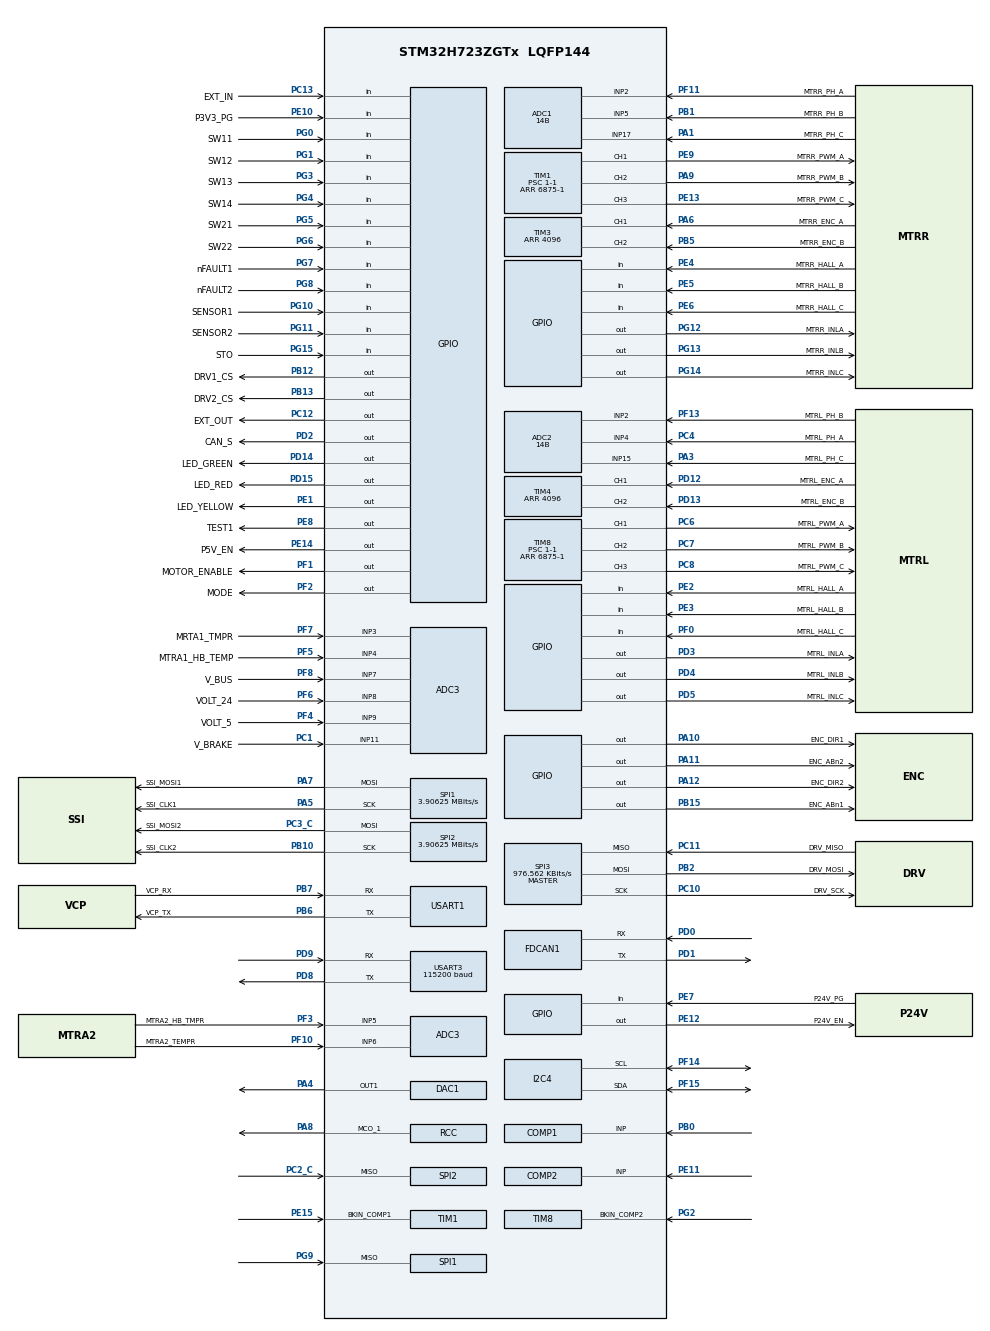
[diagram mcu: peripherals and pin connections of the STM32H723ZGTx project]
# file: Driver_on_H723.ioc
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ADC1.ClockPrescaler=ADC_CLOCK_ASYNC_DIV4
ADC1.ClockPrescalerADC3=ADC_CLOCK_ASYNC_DIV1
ADC1.ConversionDataManagement=ADC_CONVERSIONDATA_DR
ADC1.EnableInjectedConversion=ENABLE
ADC1.EnableRegularConversion=DISABLE
ADC1.ExternalTrigInjecConv=ADC_EXTERNALTRIGINJEC_T1_TRGO
ADC1.ExternalTrigInjecConvEdge=ADC_EXTERNALTRIGINJECCONV_EDGE_RISINGFALLING
ADC1.InjNumberOfConversion=2
ADC1.InjectedChannel-1\#ChannelInjectedConversion=ADC_CHANNEL_2
ADC1.InjectedChannel-2\#ChannelInjectedConversion=ADC_CHANNEL_5
ADC1.InjectedOffsetNumber-1\#ChannelInjectedConversion=ADC_OFFSET_NONE
ADC1.InjectedOffsetNumber-2\#ChannelInjectedConversion=ADC_OFFSET_NONE
ADC1.InjectedOffsetSaturation-1\#ChannelInjectedConversion=DISABLE
ADC1.InjectedOffsetSaturation-2\#ChannelInjectedConversion=DISABLE
ADC1.InjectedRank-1\#ChannelInjectedConversion=1
ADC1.InjectedRank-2\#ChannelInjectedConversion=2
ADC1.InjectedSamplingTime-1\#ChannelInjectedConversion=ADC_SAMPLETIME_1CYCLE_5
ADC1.InjectedSamplingTime-2\#ChannelInjectedConversion=ADC_SAMPLETIME_1CYCLE_5
ADC1.Overrun=ADC_OVR_DATA_PRESERVED
ADC1.Resolution=ADC_RESOLUTION_14B
ADC1.injectedQueueMode=DISABLE
ADC1.master=1
ADC2.ClockPrescaler=ADC_CLOCK_ASYNC_DIV4
ADC2.ClockPrescalerADC3=ADC_CLOCK_ASYNC_DIV1
ADC2.ConversionDataManagement=ADC_CONVERSIONDATA_DR
ADC2.EnableInjectedConversion=ENABLE
ADC2.EnableRegularConversion=DISABLE
ADC2.ExternalTrigInjecConv=ADC_EXTERNALTRIGINJEC_T8_TRGO
ADC2.ExternalTrigInjecConvEdge=ADC_EXTERNALTRIGINJECCONV_EDGE_RISINGFALLING
ADC2.InjNumberOfConversion=2
ADC2.InjectedChannel-7\#ChannelInjectedConversion=ADC_CHANNEL_4
ADC2.InjectedChannel-8\#ChannelInjectedConversion=ADC_CHANNEL_2
ADC2.InjectedOffsetNumber-7\#ChannelInjectedConversion=ADC_OFFSET_NONE
ADC2.InjectedOffsetNumber-8\#ChannelInjectedConversion=ADC_OFFSET_NONE
ADC2.InjectedOffsetSaturation-7\#ChannelInjectedConversion=DISABLE
ADC2.InjectedOffsetSaturation-8\#ChannelInjectedConversion=DISABLE
ADC2.InjectedRank-7\#ChannelInjectedConversion=1
ADC2.InjectedRank-8\#ChannelInjectedConversion=2
ADC2.InjectedSamplingTime-7\#ChannelInjectedConversion=ADC_SAMPLETIME_1CYCLE_5
ADC2.InjectedSamplingTime-8\#ChannelInjectedConversion=ADC_SAMPLETIME_1CYCLE_5
ADC2.Resolution=ADC_RESOLUTION_14B
ADC3.Channel-0\#ChannelRegularConversion=ADC_CHANNEL_3
ADC3.Channel-1\#ChannelRegularConversion=ADC_CHANNEL_4
ADC3.Channel-10\#ChannelRegularConversion=ADC_CHANNEL_VREFINT
ADC3.Channel-2\#ChannelRegularConversion=ADC_CHANNEL_5
ADC3.Channel-3\#ChannelRegularConversion=ADC_CHANNEL_6
ADC3.Channel-4\#ChannelRegularConversion=ADC_CHANNEL_7
ADC3.Channel-5\#ChannelRegularConversion=ADC_CHANNEL_8
ADC3.Channel-6\#ChannelRegularConversion=ADC_CHANNEL_9
ADC3.Channel-7\#ChannelRegularConversion=ADC_CHANNEL_11
ADC3.Channel-8\#ChannelRegularConversion=ADC_CHANNEL_VBAT
ADC3.Channel-9\#ChannelRegularConversion=ADC_CHANNEL_TEMPSENSOR
ADC3.ClockPrescaler=ADC_CLOCK_ASYNC_DIV4
ADC3.ClockPrescalerADC3=ADC_CLOCK_ASYNC_DIV1
ADC3.ContinuousConvMode=ENABLE
ADC3.DMAContinuousRequests=DISABLE
ADC3.NbrOfConversion=11
ADC3.NbrOfConversionFlag=1
ADC3.OffsetNumber-1\#ChannelRegularConversion=ADC_OFFSET_NONE
ADC3.OffsetNumber-10\#ChannelRegularConversion=ADC_OFFSET_NONE
ADC3.OffsetNumber-2\#ChannelRegularConversion=ADC_OFFSET_NONE
ADC3.OffsetNumber-3\#ChannelRegularConversion=ADC_OFFSET_NONE
ADC3.OffsetNumber-4\#ChannelRegularConversion=ADC_OFFSET_NONE
ADC3.OffsetNumber-5\#ChannelRegularConversion=ADC_OFFSET_NONE
ADC3.OffsetNumber-6\#ChannelRegularConversion=ADC_OFFSET_NONE
ADC3.OffsetNumber-7\#ChannelRegularConversion=ADC_OFFSET_NONE
ADC3.OffsetNumber-8\#ChannelRegularConversion=ADC_OFFSET_NONE
ADC3.OffsetNumber-9\#ChannelRegularConversion=ADC_OFFSET_NONE
ADC3.OffsetSign-1\#ChannelRegularConversion=ADC3_OFFSET_SIGN_NEGATIVE
ADC3.OffsetSign-10\#ChannelRegularConversion=ADC3_OFFSET_SIGN_NEGATIVE
ADC3.OffsetSign-2\#ChannelRegularConversion=ADC3_OFFSET_SIGN_NEGATIVE
ADC3.OffsetSign-3\#ChannelRegularConversion=ADC3_OFFSET_SIGN_NEGATIVE
ADC3.OffsetSign-4\#ChannelRegularConversion=ADC3_OFFSET_SIGN_NEGATIVE
ADC3.OffsetSign-5\#ChannelRegularConversion=ADC3_OFFSET_SIGN_NEGATIVE
ADC3.OffsetSign-6\#ChannelRegularConversion=ADC3_OFFSET_SIGN_NEGATIVE
ADC3.OffsetSign-7\#ChannelRegularConversion=ADC3_OFFSET_SIGN_NEGATIVE
ADC3.OffsetSign-8\#ChannelRegularConversion=ADC3_OFFSET_SIGN_NEGATIVE
ADC3.OffsetSign-9\#ChannelRegularConversion=ADC3_OFFSET_SIGN_NEGATIVE
ADC3.Rank-1\#ChannelRegularConversion=2
ADC3.Rank-10\#ChannelRegularConversion=11
ADC3.Rank-2\#ChannelRegularConversion=3
ADC3.Rank-3\#ChannelRegularConversion=4
ADC3.Rank-4\#ChannelRegularConversion=5
ADC3.Rank-5\#ChannelRegularConversion=6
ADC3.Rank-6\#ChannelRegularConversion=7
ADC3.Rank-7\#ChannelRegularConversion=8
ADC3.Rank-8\#ChannelRegularConversion=9
ADC3.Rank-9\#ChannelRegularConversion=10
ADC3.SamplingTime-0\#ChannelRegularConversion=ADC3_SAMPLETIME_2CYCLES_5
ADC3.SamplingTime-1\#ChannelRegularConversion=ADC3_SAMPLETIME_2CYCLES_5
ADC3.SamplingTime-10\#ChannelRegularConversion=ADC3_SAMPLETIME_2CYCLES_5
ADC3.SamplingTime-2\#ChannelRegularConversion=ADC3_SAMPLETIME_2CYCLES_5
ADC3.SamplingTime-3\#ChannelRegularConversion=ADC3_SAMPLETIME_2CYCLES_5
ADC3.SamplingTime-4\#ChannelRegularConversion=ADC3_SAMPLETIME_2CYCLES_5
ADC3.SamplingTime-5\#ChannelRegularConversion=ADC3_SAMPLETIME_2CYCLES_5
ADC3.SamplingTime-6\#ChannelRegularConversion=ADC3_SAMPLETIME_2CYCLES_5
ADC3.SamplingTime-7\#ChannelRegularConversion=ADC3_SAMPLETIME_2CYCLES_5
ADC3.SamplingTime-8\#ChannelRegularConversion=ADC3_SAMPLETIME_2CYCLES_5
ADC3.SamplingTime-9\#ChannelRegularConversion=ADC3_SAMPLETIME_2CYCLES_5
DAC1.DAC_Channel-DAC_OUT1=DAC_CHANNEL_1
Dma.ADC3.0.Direction=DMA_PERIPH_TO_MEMORY
Dma.ADC3.0.EventEnable=DISABLE
Dma.ADC3.0.FIFOMode=DMA_FIFOMODE_DISABLE
Dma.ADC3.0.Instance=DMA1_Stream0
Dma.ADC3.0.MemDataAlignment=DMA_MDATAALIGN_HALFWORD
Dma.ADC3.0.MemInc=DMA_MINC_ENABLE
Dma.ADC3.0.Mode=DMA_CIRCULAR
Dma.ADC3.0.PeriphDataAlignment=DMA_PDATAALIGN_HALFWORD
Dma.ADC3.0.PeriphInc=DMA_PINC_DISABLE
Dma.ADC3.0.Polarity=HAL_DMAMUX_REQ_GEN_RISING
Dma.ADC3.0.Priority=DMA_PRIORITY_LOW
Dma.ADC3.0.RequestNumber=1
Dma.ADC3.0.SignalID=NONE
Dma.ADC3.0.SyncEnable=DISABLE
Dma.ADC3.0.SyncPolarity=HAL_DMAMUX_SYNC_NO_EVENT
Dma.ADC3.0.SyncRequestNumber=1
Dma.ADC3.0.SyncSignalID=NONE
Dma.Request0=ADC3
FDCAN1.AutoRetransmission=ENABLE
FDCAN1.CalculateBaudRateNominal=1920013
FDCAN1.CalculateTimeBitNominal=520
FDCAN1.CalculateTimeQuantumNominal=104.16593817054758
FDCAN1.DataPrescaler=1
FDCAN1.DataSyncJumpWidth=1
FDCAN1.DataTimeSeg1=1
FDCAN1.DataTimeSeg2=1
FDCAN1.FrameFormat=FDCAN_FRAME_FD_NO_BRS
FDCAN1.NominalPrescaler=10
FDCAN1.NominalSyncJumpWidth=1
FDCAN1.NominalTimeSeg1=2
FDCAN1.NominalTimeSeg2=2
FDCAN1.RxBufferSize=FDCAN_DATA_BYTES_64
FDCAN1.RxFifo0ElmtSize=FDCAN_DATA_BYTES_64
FDCAN1.RxFifo0ElmtsNbr=10
FDCAN1.RxFifo1ElmtSize=FDCAN_DATA_BYTES_64
FDCAN1.StdFiltersNbr=2
FDCAN1.TxElmtSize=FDCAN_DATA_BYTES_64
FDCAN1.TxFifoQueueElmtsNbr=2
FREERTOS.BinarySemaphores01=RXSEM,Static,RXSEMControlBlock
FREERTOS.Tasks01=defaultTask,24,512,StartDefaultTask,Default,NULL,Dynamic,NULL,NULL
FREERTOS.configENABLE_FPU=1
FREERTOS.configGENERATE_RUN_TIME_STATS=1
FREERTOS.configMINIMAL_STACK_SIZE=512
FREERTOS.configTICK_RATE_HZ=1000
FREERTOS.configUSE_NEWLIB_REENTRANT=1
I2C4.Timing=0x60404E72
Mcu.Family=STM32H7
Mcu.Name=STM32H723ZGTx
Mcu.Package=LQFP144
NVIC.ADC_IRQn=true\:5\:0\:true\:false\:true\:true\:true\:true\:true
NVIC.DMA1_Stream0_IRQn=true\:7\:0\:true\:false\:true\:true\:false\:true\:true
NVIC.FDCAN1_IT0_IRQn=true\:6\:0\:true\:false\:true\:true\:true\:true\:true
NVIC.PriorityGroup=NVIC_PRIORITYGROUP_4
NVIC.TIM1_UP_IRQn=true\:6\:0\:true\:false\:true\:true\:true\:true\:true
NVIC.TIM2_IRQn=true\:6\:0\:true\:false\:true\:false\:false\:true\:true
NVIC.TimeBase=TIM2_IRQn
NVIC.TimeBaseIP=TIM2
PA0.Signal=ADC1_INP16
PA1.GPIO_Label=MTRR_PH_C
PA1.Mode=IN17-Single-Ended
PA1.Signal=ADC1_INP17
PA10.GPIO_Label=ENC_DIR1
PA10.Signal=GPIO_Output
PA11.GPIO_Label=ENC_ABn2
PA11.PinState=GPIO_PIN_RESET
PA11.Signal=GPIO_Output
PA12.GPIO_Label=ENC_DIR2
PA12.Signal=GPIO_Output
PA13(JTMS/SWDIO).GPIO_Label=SWDIO
PA13(JTMS/SWDIO).Mode=JTAG_5_pins
PA13(JTMS/SWDIO).Signal=DEBUG_JTMS-SWDIO
PA14(JTCK/SWCLK).GPIO_Label=SWCLK
PA14(JTCK/SWCLK).Mode=JTAG_5_pins
PA14(JTCK/SWCLK).Signal=DEBUG_JTCK-SWCLK
PA15(JTDI).Mode=JTAG_5_pins
PA15(JTDI).Signal=DEBUG_JTDI
PA3.GPIO_Label=MTRL_PH_C
PA3.Signal=ADCx_INP15
PA4.Signal=COMP_DAC11_group
PA5.GPIO_Label=SSI_CLK1
PA5.Mode=Full_Duplex_Master
PA5.Signal=SPI1_SCK
PA6.GPIO_Label=MTRR_ENC_A
PA6.Signal=S_TIM3_CH1
PA7.GPIO_Label=SSI_MOSI1
PA7.Mode=Full_Duplex_Master
PA7.Signal=SPI1_MOSI
PA8.Mode=Clock-out-1
PA8.Signal=RCC_MCO_1
PA9.GPIO_Label=MTRR_PWM_B
PA9.Signal=S_TIM1_CH2
PB0.Mode=INP
PB0.Signal=COMP1_INP
PB1.GPIO_Label=MTRR_PH_B
PB1.Signal=ADCx_INP5
PB10.GPIO_Label=SSI_CLK2
PB10.Mode=Full_Duplex_Master
PB10.Signal=SPI2_SCK
PB12.GPIO_Label=DRV1_CS
PB12.Signal=GPIO_Output
PB13.GPIO_Label=DRV2_CS
PB13.Signal=GPIO_Output
PB15.GPIO_Label=ENC_ABn1
PB15.PinState=GPIO_PIN_RESET
PB15.Signal=GPIO_Output
PB2.GPIO_Label=DRV_MOSI
PB2.Mode=Full_Duplex_Master
PB2.Signal=SPI3_MOSI
PB3(JTDO/TRACESWO).GPIO_Label=SWO
PB3(JTDO/TRACESWO).Mode=JTAG_5_pins
PB3(JTDO/TRACESWO).Signal=DEBUG_JTDO-SWO
PB4(NJTRST).Mode=JTAG_5_pins
PB4(NJTRST).Signal=DEBUG_JTRST
PB5.GPIO_Label=MTRR_ENC_B
PB5.Signal=S_TIM3_CH2
PB6.GPIO_Label=VCP_TX
PB6.Mode=Asynchronous
PB6.Signal=USART1_TX
PB7.GPIO_Label=VCP_RX
PB7.Mode=Asynchronous
PB7.Signal=USART1_RX
PC1.GPIO_Label=V_BRAKE
PC1.GPIO_Mode=GPIO_MODE_ANALOG
PC1.GPIO_PuPd=GPIO_NOPULL
PC1.Signal=ADCx_INP11
PC10.GPIO_Label=DRV_SCK
PC10.Mode=Full_Duplex_Master
PC10.Signal=SPI3_SCK
PC11.GPIO_Label=DRV_MISO
PC11.Mode=Full_Duplex_Master
PC11.Signal=SPI3_MISO
PC12.GPIO_Label=EXT_OUT
PC12.Signal=GPIO_Output
PC13.GPIO_Label=EXT_IN
PC13.Signal=GPIO_Input
PC14-OSC32_IN.Signal=RCC_OSC32_IN
PC15-OSC32_OUT.Signal=RCC_OSC32_OUT
PC2_C.Mode=Full_Duplex_Master
PC2_C.Signal=SPI2_MISO
PC3_C.GPIO_Label=SSI_MOSI2
PC3_C.Mode=Full_Duplex_Master
PC3_C.Signal=SPI2_MOSI
PC4.GPIO_Label=MTRL_PH_A
PC4.Signal=ADCx_INP4
PC6.GPIO_Label=MTRL_PWM_A
PC6.Signal=S_TIM8_CH1
PC7.GPIO_Label=MTRL_PWM_B
PC7.Signal=S_TIM8_CH2
PC8.GPIO_Label=MTRL_PWM_C
PC8.Signal=S_TIM8_CH3
PD0.Mode=FDCAN_Activate
PD0.Signal=FDCAN1_RX
PD1.Mode=FDCAN_Activate
PD1.Signal=FDCAN1_TX
PD12.GPIO_Label=MTRL_ENC_A
PD12.Signal=S_TIM4_CH1
PD13.GPIO_Label=MTRL_ENC_B
PD13.Signal=S_TIM4_CH2
PD14.GPIO_Label=LED_GREEN
PD14.Signal=GPIO_Output
PD15.GPIO_Label=LED_RED
PD15.PinState=GPIO_PIN_SET
PD15.Signal=GPIO_Output
PD2.GPIO_Label=CAN_S
PD2.Signal=GPIO_Output
PD3.GPIO_Label=MTRL_INLA
PD3.Signal=GPIO_Output
PD4.GPIO_Label=MTRL_INLB
PD4.Signal=GPIO_Output
PD5.GPIO_Label=MTRL_INLC
PD5.Signal=GPIO_Output
PD8.GPIO_ModeDefaultPP=GPIO_MODE_AF_PP
PD8.GPIO_PuPd=GPIO_NOPULL
PD8.GPIO_Speed=GPIO_SPEED_FREQ_LOW
PD8.Mode=Asynchronous
PD8.Signal=USART3_TX
PD9.GPIO_ModeDefaultPP=GPIO_MODE_AF_PP
PD9.GPIO_PuPd=GPIO_NOPULL
PD9.GPIO_Speed=GPIO_SPEED_FREQ_LOW
PD9.Mode=Asynchronous
PD9.Signal=USART3_RX
PE1.GPIO_Label=LED_YELLOW
PE1.Signal=GPIO_Output
PE10.GPIO_Label=P3V3_PG
PE10.Signal=GPIO_Input
PE11.Mode=INP
PE11.Signal=COMP2_INP
PE12.GPIO_Label=P24V_EN
PE12.Signal=GPIO_Output
PE13.GPIO_Label=MTRR_PWM_C
PE13.Signal=S_TIM1_CH3
PE14.GPIO_Label=P5V_EN
PE14.Signal=GPIO_Output
PE15.Mode=ExternalOutput_TIM1BKIN
PE15.Signal=TIM1_BKIN_COMP1
PE2.GPIO_Label=MTRL_HALL_A
PE2.Signal=GPIO_Input
PE3.GPIO_Label=MTRL_HALL_B
PE3.Signal=GPIO_Input
PE4.GPIO_Label=MTRR_HALL_A
PE4.Signal=GPIO_Input
PE5.GPIO_Label=MTRR_HALL_B
PE5.Signal=GPIO_Input
PE6.GPIO_Label=MTRR_HALL_C
PE6.Signal=GPIO_Input
PE7.GPIO_Label=P24V_PG
PE7.Signal=GPIO_Input
PE8.GPIO_Label=TEST1
PE8.Signal=GPIO_Output
PE9.GPIO_Label=MTRR_PWM_A
PE9.Signal=S_TIM1_CH1
PF0.GPIO_Label=MTRL_HALL_C
PF0.Signal=GPIO_Input
PF1.GPIO_Label=MOTOR_ENABLE
PF1.GPIO_PuPd=GPIO_NOPULL
PF1.Signal=GPIO_Output
PF10.GPIO_Label=MTRA2_TEMPR
PF10.GPIO_Mode=GPIO_MODE_ANALOG
PF10.GPIO_PuPd=GPIO_NOPULL
PF10.Mode=IN6-Single-Ended
PF10.Signal=ADC3_INP6
PF11.GPIO_Label=MTRR_PH_A
PF11.Mode=IN2-Single-Ended
PF11.Signal=ADC1_INP2
PF13.GPIO_Label=MTRL_PH_B
PF13.Mode=IN2-Single-Ended
PF13.Signal=ADC2_INP2
PF14.Mode=I2C
PF14.Signal=I2C4_SCL
PF15.Mode=I2C
PF15.Signal=I2C4_SDA
PF2.GPIO_Label=MODE
PF2.Signal=GPIO_Output
PF3.GPIO_Label=MTRA2_HB_TMPR
PF3.GPIO_Mode=GPIO_MODE_ANALOG
PF3.GPIO_PuPd=GPIO_NOPULL
PF3.Mode=IN5-Single-Ended
PF3.Signal=ADC3_INP5
PF4.GPIO_Label=VOLT_5
PF4.GPIO_Mode=GPIO_MODE_ANALOG
PF4.GPIO_PuPd=GPIO_NOPULL
PF4.Mode=IN9-Single-Ended
PF4.Signal=ADC3_INP9
PF5.GPIO_Label=MTRA1_HB_TEMP
PF5.GPIO_Mode=GPIO_MODE_ANALOG
PF5.GPIO_PuPd=GPIO_NOPULL
PF5.Mode=IN4-Single-Ended
PF5.Signal=ADC3_INP4
PF6.GPIO_Label=VOLT_24
PF6.GPIO_Mode=GPIO_MODE_ANALOG
PF6.GPIO_PuPd=GPIO_NOPULL
PF6.Mode=IN8-Single-Ended
PF6.Signal=ADC3_INP8
PF7.GPIO_Label=MRTA1_TMPR
PF7.GPIO_Mode=GPIO_MODE_ANALOG
PF7.GPIO_PuPd=GPIO_NOPULL
PF7.Mode=IN3-Single-Ended
PF7.Signal=ADC3_INP3
PF8.GPIO_Label=V_BUS
PF8.GPIO_Mode=GPIO_MODE_ANALOG
PF8.GPIO_PuPd=GPIO_NOPULL
PF8.Mode=IN7-Single-Ended
PF8.Signal=ADC3_INP7
PG0.GPIO_Label=SW11
PG0.Signal=GPIO_Input
PG1.GPIO_Label=SW12
PG1.Signal=GPIO_Input
PG10.GPIO_Label=SENSOR1
PG10.Signal=GPIO_Input
PG11.GPIO_Label=SENSOR2
PG11.Signal=GPIO_Input
PG12.GPIO_Label=MTRR_INLA
PG12.Signal=GPIO_Output
PG13.GPIO_Label=MTRR_INLB
PG13.Signal=GPIO_Output
PG14.GPIO_Label=MTRR_INLC
PG14.Signal=GPIO_Output
PG15.GPIO_Label=STO
PG15.Signal=GPIO_Input
PG2.Mode=ExternalOutput_TIM8BKIN
PG2.Signal=TIM8_BKIN_COMP2
PG3.GPIO_Label=SW13
PG3.Signal=GPIO_Input
PG4.GPIO_Label=SW14
PG4.Signal=GPIO_Input
PG5.GPIO_Label=SW21
PG5.Signal=GPIO_Input
PG6.GPIO_Label=SW22
PG6.Signal=GPIO_Input
PG7.GPIO_Label=nFAULT1
PG7.Signal=GPIO_Input
PG8.GPIO_Label=nFAULT2
PG8.Signal=GPIO_Input
PG9.Mode=Full_Duplex_Master
PG9.Signal=SPI1_MISO
PH0-OSC_IN.Mode=HSE-External-Clock-Source
PH0-OSC_IN.Signal=RCC_OSC_IN
PH1-OSC_OUT.Signal=RCC_OSC_OUT
ProjectManager.HeapSize=0x200
ProjectManager.StackSize=0x400
ProjectManager.TargetToolchain=STM32CubeIDE
RCC.ADCFreq_Value=96000671.38671875
RCC.APB1Freq_Value=137500000
RCC.APB2Freq_Value=137500000
RCC.APB3Freq_Value=137500000
RCC.APB4Freq_Value=137500000
RCC.CortexFreq_Value=550000000
RCC.D1PPRE=RCC_APB3_DIV2
RCC.D2PPRE1=RCC_APB1_DIV2
RCC.D2PPRE2=RCC_APB2_DIV2
RCC.D3PPRE=RCC_APB4_DIV2
RCC.DIVM1=2
RCC.DIVM2=2
RCC.DIVM3=3
RCC.DIVN1=44
RCC.DIVN2=15
RCC.DIVN3=45
RCC.DIVP1=1
RCC.DIVP3=3
RCC.DIVQ1=3
RCC.FDCANCLockSelection=RCC_FDCANCLKSOURCE_PLL2
RCC.HCLKFreq_Value=275000000
RCC.HPRE=RCC_HCLK_DIV2
RCC.HSE_VALUE=25000000
RCC.PLL1_VCI_Range-AdvancedSettings=RCC_PLL1VCIRANGE_0
RCC.PLL2FRACN=2950
RCC.PLL3FRACN=0
RCC.PLL3_VCO_SEL-AdvancedSettings=RCC_PLL3VCOMEDIUM
RCC.PLLFRACN=0
RCC.PLLSourceVirtual=RCC_PLLSOURCE_HSE
RCC.RCC_MCO1Source=RCC_MCO1SOURCE_PLL1QCLK
RCC.RCC_MCODiv1=RCC_MCODIV_10
RCC.SPI123CLockSelection=RCC_SPI123CLKSOURCE_PLL3
RCC.SYSCLKFreq_VALUE=550000000
RCC.SYSCLKSource=RCC_SYSCLKSOURCE_PLLCLK
RCC.USBCLockSelection=RCC_USBCLKSOURCE_HSI48
RCC.USBFreq_Value=48000000
SH.ADCx_INP11.0=ADC3_INP11,IN11-Single-Ended
SH.ADCx_INP15.0=ADC2_INP15,IN15-Single-Ended
SH.ADCx_INP4.0=ADC2_INP4,IN4-Single-Ended
SH.ADCx_INP5.0=ADC1_INP5,IN5-Single-Ended
SH.COMP_DAC11_group.0=DAC1_OUT1,DAC_OUT1
SH.S_TIM1_CH1.0=TIM1_CH1,PWM Generation1 CH1
SH.S_TIM1_CH2.0=TIM1_CH2,PWM Generation2 CH2
SH.S_TIM1_CH3.0=TIM1_CH3,PWM Generation3 CH3
SH.S_TIM3_CH1.0=TIM3_CH1,Encoder_Interface
SH.S_TIM3_CH2.0=TIM3_CH2,Encoder_Interface
SH.S_TIM4_CH1.0=TIM4_CH1,Encoder_Interface
SH.S_TIM4_CH2.0=TIM4_CH2,Encoder_Interface
SH.S_TIM8_CH1.0=TIM8_CH1,PWM Generation1 CH1
SH.S_TIM8_CH2.0=TIM8_CH2,PWM Generation2 CH2
SH.S_TIM8_CH3.0=TIM8_CH3,PWM Generation3 CH3
SPI1.BaudRatePrescaler=SPI_BAUDRATEPRESCALER_32
SPI1.CLKPhase=SPI_PHASE_2EDGE
SPI1.CLKPolarity=SPI_POLARITY_HIGH
SPI1.CalculateBaudRate=3.90625 MBits/s
SPI1.DataSize=SPI_DATASIZE_31BIT
SPI1.Direction=SPI_DIRECTION_2LINES
SPI1.FirstBit=SPI_FIRSTBIT_MSB
SPI1.Mode=SPI_MODE_MASTER
SPI1.VirtualType=VM_MASTER
SPI2.BaudRatePrescaler=SPI_BAUDRATEPRESCALER_32
SPI2.CLKPhase=SPI_PHASE_2EDGE
SPI2.CLKPolarity=SPI_POLARITY_HIGH
SPI2.CalculateBaudRate=3.90625 MBits/s
SPI2.DataSize=SPI_DATASIZE_31BIT
SPI2.Direction=SPI_DIRECTION_2LINES
SPI2.FirstBit=SPI_FIRSTBIT_MSB
SPI2.Mode=SPI_MODE_MASTER
SPI2.VirtualType=VM_MASTER
SPI3.BaudRatePrescaler=SPI_BAUDRATEPRESCALER_128
SPI3.CLKPhase=SPI_PHASE_2EDGE
SPI3.CLKPolarity=SPI_POLARITY_LOW
SPI3.CalculateBaudRate=976.562 KBits/s
SPI3.DataSize=SPI_DATASIZE_16BIT
SPI3.Direction=SPI_DIRECTION_2LINES
SPI3.Mode=SPI_MODE_MASTER
SPI3.VirtualType=VM_MASTER
TIM1.BreakState=TIM_BREAK_DISABLE
TIM1.Channel-Output\ Compare4\ No\ Output=TIM_CHANNEL_4
TIM1.Channel-PWM\ Generation1\ CH1=TIM_CHANNEL_1
TIM1.Channel-PWM\ Generation2\ CH2=TIM_CHANNEL_2
TIM1.Channel-PWM\ Generation3\ CH3=TIM_CHANNEL_3
TIM1.CounterMode=TIM_COUNTERMODE_CENTERALIGNED3
TIM1.OCMode_4=TIM_OCMODE_TOGGLE
TIM1.OCMode_PWM-PWM\ Generation1\ CH1=TIM_OCMODE_PWM1
TIM1.OCMode_PWM-PWM\ Generation2\ CH2=TIM_OCMODE_PWM1
TIM1.OCMode_PWM-PWM\ Generation3\ CH3=TIM_OCMODE_PWM1
TIM1.Period=6875-1
TIM1.Prescaler=1-1
TIM1.Pulse-Output\ Compare4\ No\ Output=6875-1
TIM1.Pulse-PWM\ Generation1\ CH1=3437-1
TIM1.Pulse-PWM\ Generation2\ CH2=3437-1
TIM1.Pulse-PWM\ Generation3\ CH3=3437-1
TIM1.SourceBRKDigInput=TIM_BREAKINPUTSOURCE_DISABLE
TIM1.TIM_MasterOutputTrigger=TIM_TRGO_OC4REF
TIM3.CounterMode=TIM_COUNTERMODE_DOWN
TIM3.EncoderMode=TIM_ENCODERMODE_TI12
TIM3.IC1Polarity=TIM_ICPOLARITY_RISING
TIM3.IC2Polarity=TIM_ICPOLARITY_RISING
TIM3.Period=4096
TIM4.CounterMode=TIM_COUNTERMODE_DOWN
TIM4.EncoderMode=TIM_ENCODERMODE_TI12
TIM4.Period=4096
TIM8.Channel-Output\ Compare4\ No\ Output=TIM_CHANNEL_4
TIM8.Channel-PWM\ Generation1\ CH1=TIM_CHANNEL_1
TIM8.Channel-PWM\ Generation2\ CH2=TIM_CHANNEL_2
TIM8.Channel-PWM\ Generation3\ CH3=TIM_CHANNEL_3
TIM8.CounterMode=TIM_COUNTERMODE_CENTERALIGNED3
TIM8.OCMode_4=TIM_OCMODE_TOGGLE
TIM8.Period=6875-1
TIM8.Prescaler=1-1
TIM8.Pulse-Output\ Compare4\ No\ Output=6875-1
TIM8.Pulse-PWM\ Generation1\ CH1=3437-1
TIM8.Pulse-PWM\ Generation2\ CH2=3437-1
TIM8.Pulse-PWM\ Generation3\ CH3=3437-1
TIM8.SourceBRKCOMP1=TIM_BREAKINPUTSOURCE_DISABLE
TIM8.SourceBRKCOMP2=TIM_BREAKINPUTSOURCE_DISABLE
TIM8.TIM_MasterOutputTrigger=TIM_TRGO_OC4REF
USART1.VirtualMode-Asynchronous=VM_ASYNC
USART3.BaudRate=115200
USART3.VirtualMode-Asynchronous=VM_ASYNC
VP_ADC3_TempSens_Input.Mode=IN-TempSens
VP_ADC3_Vbat_Input.Mode=IN-Vbat
VP_ADC3_Vref_Input.Mode=IN-Vrefint
VP_COMP1_VS_VREFINT14.Mode=VREFINT_14
VP_COMP2_VS_VREFINT14.Mode=VREFINT_14
VP_FREERTOS_VS_CMSIS_V2.Mode=CMSIS_V2
VP_SYS_VS_tim2.Mode=TIM2
VP_TIM1_VS_ClockSourceINT.Mode=Internal
VP_TIM1_VS_no_output4.Mode=Output Compare4 No Output
VP_TIM8_VS_ClockSourceITR.Mode=TriggerSource_ITR0
VP_TIM8_VS_ControllerModeReset.Mode=Reset Mode
VP_TIM8_VS_no_output4.Mode=Output Compare4 No Output
VP_VREFBUF_V_VREFBUF.Mode=ExternalMode
board=NUCLEO-H723ZG

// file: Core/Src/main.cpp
/* USER CODE BEGIN Header */
/**
 ******************************************************************************
 * @file           : main.c
 * @brief          : Main program body
 ******************************************************************************
 * @attention
 *
 * Copyright (c) 2025 STMicroelectronics.
 * All rights reserved.
 *
 * This software is licensed under terms that can be found in the LICENSE file
 * in the root directory of this software component.
 * If no LICENSE file comes with this software, it is provided AS-IS.
 *
 ******************************************************************************
 */
/* USER CODE END Header */
#include "main.h"
#include "cmsis_os.h"
#include "adc.h"
#include "comp.h"
#include "dac.h"
#include "dma.h"
#include "fdcan.h"
#include "i2c.h"
#include "spi.h"
#include "tim.h"
#include "usart.h"
#include "gpio.h"

/* USER CODE BEGIN Includes */
#include "drv8323.h"
#include "motor_manager.h"
#include "Motor.h"
#include "ABEncoder.h"
#include "Fake_encoder.h" // or your fake encoder header
#include "HAL_PWM.h"
/* USER CODE END Includes */

/* USER CODE BEGIN PV */
Motor motorR; // Right motor
Motor motorL; // Left motor

#define VSHEN_POLE_PAIRS 1
/* USER CODE END PV */

void SystemClock_Config(void);
void PeriphCommonClock_Config(void);
void MX_FREERTOS_Init(void);

/* USER CODE BEGIN 0 */

void init_gate_driver(void)
{
  /* sip and gate driver init */
  HAL_GPIO_WritePin(MOTOR_ENABLE_GPIO_Port, MOTOR_ENABLE_Pin, GPIO_PIN_SET);
  drv8323_Init(DRV8323_2, &hspi3, DRV2_CS_GPIO_Port, DRV2_CS_Pin);
  drv8323_Init(DRV8323_1, &hspi3, DRV1_CS_GPIO_Port, DRV1_CS_Pin);
  drv8323_registers_init();
}

HAL_StatusTypeDef init_motor_adc(void)
{
  // ADC initialization
  if (HAL_ADCEx_Calibration_Start(&hadc1, ADC_CALIB_OFFSET_LINEARITY, ADC_SINGLE_ENDED) != HAL_OK)
  {
    // Calibration Error
    return HAL_ERROR;
  }
  if (HAL_ADCEx_Calibration_Start(&hadc2, ADC_CALIB_OFFSET_LINEARITY, ADC_SINGLE_ENDED) != HAL_OK)
  {
    // ADC Error
    return HAL_ERROR;
  }

  if (HAL_ADCEx_InjectedStart_IT(&hadc1) != HAL_OK)
  {
    // ADC Error
    return HAL_ERROR;
  }
  if (HAL_ADCEx_InjectedStart_IT(&hadc2) != HAL_OK)
  {
    // ADC Error
    return HAL_ERROR;
  }
  return HAL_OK;
}

ABEncoder abEncoder(4096, 20000, htim3, VSHEN_POLE_PAIRS);
FakeEncoderSim fakeEncoder(20000, 0.5);
HAL_PWM motorR_PWM;
Base_adc_sensor motorR_current_sensorPa;
volatile uint32_t *pwm_pointr;
/* USER CODE END 0 */

int main(void)
{

  /* MCU Configuration--------------------------------------------------------*/

  /* Reset of all peripherals, Initializes the Flash interface and the Systick. */
  HAL_Init();

  /* Configure the system clock */
  SystemClock_Config();

  /* Configure the peripherals common clocks */
  PeriphCommonClock_Config();

  /* Initialize all configured peripherals */
  MX_GPIO_Init();
  MX_DMA_Init();
  MX_USART3_UART_Init();
  MX_TIM3_Init();
  MX_TIM1_Init();
  MX_TIM4_Init();
  MX_ADC2_Init();
  MX_FDCAN1_Init();
  MX_USART1_UART_Init();
  MX_SPI3_Init();
  MX_ADC3_Init();
  MX_I2C4_Init();
  MX_COMP1_Init();
  MX_TIM8_Init();
  MX_DAC1_Init();
  MX_ADC1_Init();
  MX_COMP2_Init();
  MX_SPI1_Init();
  MX_SPI2_Init();
  /* USER CODE BEGIN 2 */

  //  int32_t timerFreqHz;
  //  timerFreqHz = HAL_RCC_GetPCLK1Freq() / htim1.Init.Period;

  init_gate_driver();

  HAL_TIM_Encoder_Start(&htim3, TIM_CHANNEL_ALL);
  HAL_TIM_Encoder_Start(&htim4, TIM_CHANNEL_ALL);
  // Set encoder for right motor
  motorR.setEncoder(fakeEncoder);
  //  HAL_PWM motorR_PWM(htim1.Instance->CCR1, htim1.Instance->CCR2, htim1.Instance->CCR3, htim1.Init.Period);
  motorR.setPWMDriver(motorR_PWM);
  motorR_PWM.init(&htim1.Instance->CCR1, &htim1.Instance->CCR2, &htim1.Instance->CCR3, htim1.Init.Period, &htim1);
  motorR_current_sensorPa.init_adc_sensor(&hadc1.Instance->JDR1, 1.0f, 0.0f);

  motorR.setCurrentSensors(motorR_current_sensorPa, motorR_current_sensorPa); // Using same sensor for phase B for testing
  //  pwm_pointr = &htim1.Instance->CCR1;
  // Initialize motor manager
  MotorManager::init();

  // Set up motors in motor manager
  MotorManager::setMotor(0, motorR);
  HAL_GPIO_WritePin(MTRR_INLA_GPIO_Port, MTRR_INLA_Pin, GPIO_PIN_SET); //	set INL to true
  HAL_GPIO_WritePin(MTRR_INLB_GPIO_Port, MTRR_INLB_Pin, GPIO_PIN_SET); //	set INL to true
  HAL_GPIO_WritePin(MTRR_INLC_GPIO_Port, MTRR_INLC_Pin, GPIO_PIN_SET); //	set INL to true
  init_motor_adc();
  /* USER CODE END 2 */

  /* Init scheduler */
  osKernelInitialize();

  /* Call init function for freertos objects (in cmsis_os2.c) */
  MX_FREERTOS_Init();

  /* Start scheduler */
  osKernelStart();

  /* We should never get here as control is now taken by the scheduler */

  /* Infinite loop */
  while (1)
  {

  }
}

void SystemClock_Config(void)
{
  RCC_OscInitTypeDef RCC_OscInitStruct = {0};
  RCC_ClkInitTypeDef RCC_ClkInitStruct = {0};

  /** Supply configuration update enable
   */
  HAL_PWREx_ConfigSupply(PWR_LDO_SUPPLY);

  /** Configure the main internal regulator output voltage
   */
  __HAL_PWR_VOLTAGESCALING_CONFIG(PWR_REGULATOR_VOLTAGE_SCALE0);

  while (!__HAL_PWR_GET_FLAG(PWR_FLAG_VOSRDY))
  {
  }

  /** Initializes the RCC Oscillators according to the specified parameters
   * in the RCC_OscInitTypeDef structure.
   */
  RCC_OscInitStruct.OscillatorType = RCC_OSCILLATORTYPE_HSE;
  RCC_OscInitStruct.HSEState = RCC_HSE_BYPASS;
  RCC_OscInitStruct.PLL.PLLState = RCC_PLL_ON;
  RCC_OscInitStruct.PLL.PLLSource = RCC_PLLSOURCE_HSE;
  RCC_OscInitStruct.PLL.PLLM = 2;
  RCC_OscInitStruct.PLL.PLLN = 44;
  RCC_OscInitStruct.PLL.PLLP = 1;
  RCC_OscInitStruct.PLL.PLLQ = 3;
  RCC_OscInitStruct.PLL.PLLR = 2;
  RCC_OscInitStruct.PLL.PLLRGE = RCC_PLL1VCIRANGE_3;
  RCC_OscInitStruct.PLL.PLLVCOSEL = RCC_PLL1VCOWIDE;
  RCC_OscInitStruct.PLL.PLLFRACN = 0;
  if (HAL_RCC_OscConfig(&RCC_OscInitStruct) != HAL_OK)
  {
    Error_Handler();
  }

  /** Initializes the CPU, AHB and APB buses clocks
   */
  RCC_ClkInitStruct.ClockType = RCC_CLOCKTYPE_HCLK | RCC_CLOCKTYPE_SYSCLK | RCC_CLOCKTYPE_PCLK1 | RCC_CLOCKTYPE_PCLK2 | RCC_CLOCKTYPE_D3PCLK1 | RCC_CLOCKTYPE_D1PCLK1;
  RCC_ClkInitStruct.SYSCLKSource = RCC_SYSCLKSOURCE_PLLCLK;
  RCC_ClkInitStruct.SYSCLKDivider = RCC_SYSCLK_DIV1;
  RCC_ClkInitStruct.AHBCLKDivider = RCC_HCLK_DIV2;
  RCC_ClkInitStruct.APB3CLKDivider = RCC_APB3_DIV2;
  RCC_ClkInitStruct.APB1CLKDivider = RCC_APB1_DIV2;
  RCC_ClkInitStruct.APB2CLKDivider = RCC_APB2_DIV2;
  RCC_ClkInitStruct.APB4CLKDivider = RCC_APB4_DIV2;

  if (HAL_RCC_ClockConfig(&RCC_ClkInitStruct, FLASH_LATENCY_3) != HAL_OK)
  {
    Error_Handler();
  }
  __HAL_RCC_PLLCLKOUT_ENABLE(RCC_PLL1_DIVQ);
  HAL_RCC_MCOConfig(RCC_MCO1, RCC_MCO1SOURCE_PLL1QCLK, RCC_MCODIV_10);
}

void PeriphCommonClock_Config(void)
{
  RCC_PeriphCLKInitTypeDef PeriphClkInitStruct = {0};

  /** Initializes the peripherals clock
   */
  PeriphClkInitStruct.PeriphClockSelection = RCC_PERIPHCLK_ADC | RCC_PERIPHCLK_SPI3 | RCC_PERIPHCLK_SPI2 | RCC_PERIPHCLK_SPI1 | RCC_PERIPHCLK_FDCAN;
  PeriphClkInitStruct.PLL2.PLL2M = 2;
  PeriphClkInitStruct.PLL2.PLL2N = 15;
  PeriphClkInitStruct.PLL2.PLL2P = 2;
  PeriphClkInitStruct.PLL2.PLL2Q = 2;
  PeriphClkInitStruct.PLL2.PLL2R = 2;
  PeriphClkInitStruct.PLL2.PLL2RGE = RCC_PLL2VCIRANGE_3;
  PeriphClkInitStruct.PLL2.PLL2VCOSEL = RCC_PLL2VCOWIDE;
  PeriphClkInitStruct.PLL2.PLL2FRACN = 2950;
  PeriphClkInitStruct.PLL3.PLL3M = 3;
  PeriphClkInitStruct.PLL3.PLL3N = 45;
  PeriphClkInitStruct.PLL3.PLL3P = 3;
  PeriphClkInitStruct.PLL3.PLL3Q = 2;
  PeriphClkInitStruct.PLL3.PLL3R = 2;
  PeriphClkInitStruct.PLL3.PLL3RGE = RCC_PLL3VCIRANGE_3;
  PeriphClkInitStruct.PLL3.PLL3VCOSEL = RCC_PLL3VCOWIDE;
  PeriphClkInitStruct.PLL3.PLL3FRACN = 0;
  PeriphClkInitStruct.Spi123ClockSelection = RCC_SPI123CLKSOURCE_PLL3;
  PeriphClkInitStruct.FdcanClockSelection = RCC_FDCANCLKSOURCE_PLL2;
  PeriphClkInitStruct.AdcClockSelection = RCC_ADCCLKSOURCE_PLL2;
  if (HAL_RCCEx_PeriphCLKConfig(&PeriphClkInitStruct) != HAL_OK)
  {
    Error_Handler();
  }
}

/* USER CODE BEGIN 4 */
// void HAL_ADCEx_InjectedConvCpltCallback(ADC_HandleTypeDef *hadc)
//{
//
// }
/* USER CODE END 4 */

void HAL_TIM_PeriodElapsedCallback(TIM_HandleTypeDef *htim)
{
  if (htim->Instance == TIM2)
  {
    HAL_IncTick();
  }
}

void Error_Handler(void)
{
  /* USER CODE BEGIN Error_Handler_Debug */
	  HAL_GPIO_WritePin(MTRR_INLA_GPIO_Port, MTRR_INLA_Pin, GPIO_PIN_RESET); //	set INL to true
	  HAL_GPIO_WritePin(MTRR_INLB_GPIO_Port, MTRR_INLB_Pin, GPIO_PIN_RESET); //	set INL to true
	  HAL_GPIO_WritePin(MTRR_INLC_GPIO_Port, MTRR_INLC_Pin, GPIO_PIN_RESET); //	set INL to true
  /* User can add his own implementation to report the HAL error return state */
  __disable_irq();
  while (1)
  {
  }
  /* USER CODE END Error_Handler_Debug */
}
